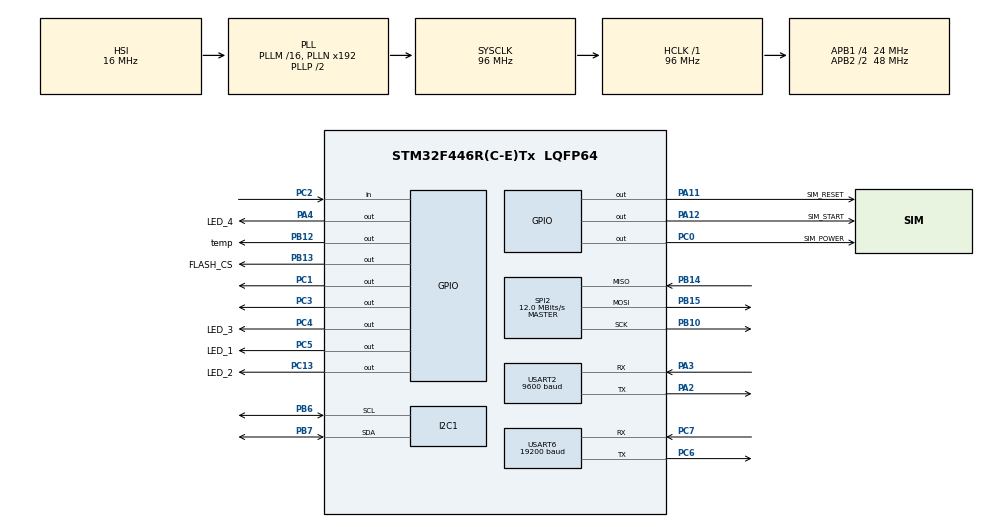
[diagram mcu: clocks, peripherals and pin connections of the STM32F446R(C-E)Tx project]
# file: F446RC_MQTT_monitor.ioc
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Dma.Request0=USART2_RX
Dma.Request1=USART2_TX
Dma.Request2=USART6_RX
Dma.Request3=USART6_TX
Dma.USART2_RX.0.Direction=DMA_PERIPH_TO_MEMORY
Dma.USART2_RX.0.FIFOMode=DMA_FIFOMODE_DISABLE
Dma.USART2_RX.0.Instance=DMA1_Stream5
Dma.USART2_RX.0.MemDataAlignment=DMA_MDATAALIGN_BYTE
Dma.USART2_RX.0.MemInc=DMA_MINC_ENABLE
Dma.USART2_RX.0.Mode=DMA_NORMAL
Dma.USART2_RX.0.PeriphDataAlignment=DMA_PDATAALIGN_BYTE
Dma.USART2_RX.0.PeriphInc=DMA_PINC_DISABLE
Dma.USART2_RX.0.Priority=DMA_PRIORITY_LOW
Dma.USART2_TX.1.Direction=DMA_MEMORY_TO_PERIPH
Dma.USART2_TX.1.FIFOMode=DMA_FIFOMODE_DISABLE
Dma.USART2_TX.1.Instance=DMA1_Stream6
Dma.USART2_TX.1.MemDataAlignment=DMA_MDATAALIGN_BYTE
Dma.USART2_TX.1.MemInc=DMA_MINC_ENABLE
Dma.USART2_TX.1.Mode=DMA_NORMAL
Dma.USART2_TX.1.PeriphDataAlignment=DMA_PDATAALIGN_BYTE
Dma.USART2_TX.1.PeriphInc=DMA_PINC_DISABLE
Dma.USART2_TX.1.Priority=DMA_PRIORITY_LOW
Dma.USART6_RX.2.Direction=DMA_PERIPH_TO_MEMORY
Dma.USART6_RX.2.FIFOMode=DMA_FIFOMODE_DISABLE
Dma.USART6_RX.2.Instance=DMA2_Stream1
Dma.USART6_RX.2.MemDataAlignment=DMA_MDATAALIGN_BYTE
Dma.USART6_RX.2.MemInc=DMA_MINC_ENABLE
Dma.USART6_RX.2.Mode=DMA_NORMAL
Dma.USART6_RX.2.PeriphDataAlignment=DMA_PDATAALIGN_BYTE
Dma.USART6_RX.2.PeriphInc=DMA_PINC_DISABLE
Dma.USART6_RX.2.Priority=DMA_PRIORITY_LOW
Dma.USART6_TX.3.Direction=DMA_MEMORY_TO_PERIPH
Dma.USART6_TX.3.FIFOMode=DMA_FIFOMODE_DISABLE
Dma.USART6_TX.3.Instance=DMA2_Stream6
Dma.USART6_TX.3.MemDataAlignment=DMA_MDATAALIGN_BYTE
Dma.USART6_TX.3.MemInc=DMA_MINC_ENABLE
Dma.USART6_TX.3.Mode=DMA_NORMAL
Dma.USART6_TX.3.PeriphDataAlignment=DMA_PDATAALIGN_BYTE
Dma.USART6_TX.3.PeriphInc=DMA_PINC_DISABLE
Dma.USART6_TX.3.Priority=DMA_PRIORITY_LOW
FREERTOS.BinarySemaphores01=PINGSem,Dynamic,NULL;SemGetData,Dynamic,NULL
FREERTOS.Mutexes01=UART1Mutex,Dynamic,NULL
FREERTOS.Queues01=debugQueue,10,message_type,0,Dynamic,NULL,NULL;SIM800SendQueue,10,message_type,0,Dynamic,NULL,NULL;RxSIM800Queue,10,message_type,0,Dynamic,NULL,NULL
FREERTOS.Tasks01=defaultTask,24,128,StartDefaultTask,Default,NULL,Dynamic,NULL,NULL;GetDataTask,25,128,StartGetDataTask,Default,NULL,Dynamic,NULL,NULL;DebugTask,24,128,StartDebugTask,Default,NULL,Dynamic,NULL,NULL;SIM800SendTask,24,256,StartSIM800SendTask,Default,NULL,Dynamic,NULL,NULL;PINGTask,24,256,PINGStartTask,Default,NULL,Dynamic,NULL,NULL;SIM800StartTask,26,256,StartSIM800Task,Default,NULL,Dynamic,NULL,NULL;MQTTConnectTask,24,256,StartMQTTConnectTask,Default,NULL,Dynamic,NULL,NULL;MessHandlerTask,24,256,StartMessHandlerTask,Default,NULL,Dynamic,NULL,NULL;myTaskGetFirm,25,512,StartGetFirmware,Default,NULL,Dynamic,NULL,NULL
FREERTOS.Timers01=PingTimer,CallbackPingTimer,osTimerPeriodic,Default,NULL,Dynamic,NULL;DataTimer,CallbackDataTimer,osTimerPeriodic,Default,NULL,Dynamic,NULL
Mcu.Family=STM32F4
Mcu.Name=STM32F446R(C-E)Tx
Mcu.Package=LQFP64
NVIC.DMA1_Stream5_IRQn=true\:5\:0\:false\:false\:true\:true\:false\:true\:true
NVIC.DMA1_Stream6_IRQn=true\:5\:0\:false\:false\:true\:true\:false\:true\:true
NVIC.DMA2_Stream1_IRQn=true\:5\:0\:false\:false\:true\:true\:false\:true\:true
NVIC.DMA2_Stream6_IRQn=true\:5\:0\:false\:false\:true\:true\:false\:true\:true
NVIC.PriorityGroup=NVIC_PRIORITYGROUP_4
NVIC.TIM1_UP_TIM10_IRQn=true\:0\:0\:false\:false\:true\:false\:false\:true\:true
NVIC.TimeBase=TIM1_UP_TIM10_IRQn
NVIC.TimeBaseIP=TIM1
NVIC.USART2_IRQn=true\:5\:0\:false\:false\:true\:true\:true\:true\:true
NVIC.USART6_IRQn=true\:5\:0\:false\:false\:true\:true\:true\:true\:true
PA11.GPIO_Label=SIM_RESET
PA11.Signal=GPIO_Output
PA12.GPIO_Label=SIM_START
PA12.Signal=GPIO_Output
PA13.Mode=Serial_Wire
PA13.Signal=SYS_JTMS-SWDIO
PA14.Mode=Serial_Wire
PA14.Signal=SYS_JTCK-SWCLK
PA2.Mode=Asynchronous
PA2.Signal=USART2_TX
PA3.Mode=Asynchronous
PA3.Signal=USART2_RX
PA4.GPIO_Label=LED_4
PA4.PinState=GPIO_PIN_SET
PA4.Signal=GPIO_Output
PB10.Mode=Full_Duplex_Master
PB10.Signal=SPI2_SCK
PB12.GPIO_Label=temp
PB12.Signal=GPIO_Output
PB13.GPIO_Label=FLASH_CS
PB13.PinState=GPIO_PIN_SET
PB13.Signal=GPIO_Output
PB14.Mode=Full_Duplex_Master
PB14.Signal=SPI2_MISO
PB15.Mode=Full_Duplex_Master
PB15.Signal=SPI2_MOSI
PB6.Mode=I2C
PB6.Signal=I2C1_SCL
PB7.Mode=I2C
PB7.Signal=I2C1_SDA
PC0.GPIO_Label=SIM_POWER
PC0.Signal=GPIO_Output
PC1.PinState=GPIO_PIN_SET
PC1.Signal=GPIO_Output
PC13.GPIO_Label=LED_2
PC13.PinState=GPIO_PIN_SET
PC13.Signal=GPIO_Output
PC2.Signal=GPIO_Input
PC3.PinState=GPIO_PIN_SET
PC3.Signal=GPIO_Output
PC4.GPIO_Label=LED_3
PC4.PinState=GPIO_PIN_SET
PC4.Signal=GPIO_Output
PC5.GPIO_Label=LED_1
PC5.PinState=GPIO_PIN_SET
PC5.Signal=GPIO_Output
PC6.Mode=Asynchronous
PC6.Signal=USART6_TX
PC7.Mode=Asynchronous
PC7.Signal=USART6_RX
ProjectManager.HeapSize=0x200
ProjectManager.StackSize=0x400
ProjectManager.TargetToolchain=STM32CubeIDE
RCC.AHBFreq_Value=96000000
RCC.APB1CLKDivider=RCC_HCLK_DIV4
RCC.APB1Freq_Value=24000000
RCC.APB1TimFreq_Value=48000000
RCC.APB2CLKDivider=RCC_HCLK_DIV2
RCC.APB2Freq_Value=48000000
RCC.APB2TimFreq_Value=96000000
RCC.CortexFreq_Value=96000000
RCC.HCLKFreq_Value=96000000
RCC.SYSCLKFreq_VALUE=96000000
RCC.SYSCLKSource=RCC_SYSCLKSOURCE_PLLCLK
RCC.USBFreq_Value=96000000
RCC.VCOOutputFreq_Value=192000000
SPI2.CalculateBaudRate=12.0 MBits/s
SPI2.Direction=SPI_DIRECTION_2LINES
SPI2.Mode=SPI_MODE_MASTER
SPI2.VirtualType=VM_MASTER
USART2.BaudRate=9600
USART2.VirtualMode=VM_ASYNC
USART6.BaudRate=19200
USART6.VirtualMode=VM_ASYNC
VP_FREERTOS_VS_CMSIS_V2.Mode=CMSIS_V2
VP_SYS_VS_tim1.Mode=TIM1
board=custom

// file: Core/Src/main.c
/* USER CODE BEGIN Header */
//!!!! COMMENT MQTTConnectTaskHandle, PINGTaskHandle, myTaskGetFirmHandle
//AND RESET ALL SEMAPHORES !!!!!!!
/**
  ******************************************************************************
  * @file           : main.c
  * @brief          : Main program body
  ******************************************************************************
  * @attention
  *
  * <h2><center>&copy; Copyright (c) 2022 STMicroelectronics.
  * All rights reserved.</center></h2>
  *
  * This software component is licensed by ST under BSD 3-Clause license,
  * the "License"; You may not use this file except in compliance with the
  * License. You may obtain a copy of the License at:
  *                        opensource.org/licenses/BSD-3-Clause
  *
  ******************************************************************************
  */
/* USER CODE END Header */
#include "main.h"
#include "cmsis_os.h"

/* USER CODE BEGIN Includes */
#include <string.h>
#include <stdlib.h>
#include "micro_delay.h"
#include "w25qxx.h"
#include "private_data.h"
#include "ModBusCRC.h"
#include "INA226.h"
/* USER CODE END Includes */

/* USER CODE BEGIN PD */
#define PING_TIME 50000  //period of sending ping package
#define BUFF_SIM_SIZE 120 //size of RX SIM buffer
#define MESSAGE_TYPE_BUFF_SIZE 90
#define GET_DATA_PERIOD 60000
/* USER CODE END PD */

/* USER CODE BEGIN PM */
typedef struct {
	char str[MESSAGE_TYPE_BUFF_SIZE];
} message_type;
/* USER CODE END PM */

I2C_HandleTypeDef hi2c1;

SPI_HandleTypeDef hspi2;

UART_HandleTypeDef huart2;
UART_HandleTypeDef huart6;
DMA_HandleTypeDef hdma_usart2_rx;
DMA_HandleTypeDef hdma_usart2_tx;
DMA_HandleTypeDef hdma_usart6_rx;
DMA_HandleTypeDef hdma_usart6_tx;

/* Definitions for defaultTask */
osThreadId_t defaultTaskHandle;
const osThreadAttr_t defaultTask_attributes = {
  .name = "defaultTask",
  .stack_size = 128 * 4,
  .priority = (osPriority_t) osPriorityNormal,
};
/* Definitions for GetDataTask */
osThreadId_t GetDataTaskHandle;
const osThreadAttr_t GetDataTask_attributes = {
  .name = "GetDataTask",
  .stack_size = 128 * 4,
  .priority = (osPriority_t) osPriorityNormal1,
};
/* Definitions for DebugTask */
osThreadId_t DebugTaskHandle;
const osThreadAttr_t DebugTask_attributes = {
  .name = "DebugTask",
  .stack_size = 128 * 4,
  .priority = (osPriority_t) osPriorityNormal,
};
/* Definitions for SIM800SendTask */
osThreadId_t SIM800SendTaskHandle;
const osThreadAttr_t SIM800SendTask_attributes = {
  .name = "SIM800SendTask",
  .stack_size = 256 * 4,
  .priority = (osPriority_t) osPriorityNormal,
};
/* Definitions for PINGTask */
osThreadId_t PINGTaskHandle;
const osThreadAttr_t PINGTask_attributes = {
  .name = "PINGTask",
  .stack_size = 256 * 4,
  .priority = (osPriority_t) osPriorityNormal,
};
/* Definitions for SIM800StartTask */
osThreadId_t SIM800StartTaskHandle;
const osThreadAttr_t SIM800StartTask_attributes = {
  .name = "SIM800StartTask",
  .stack_size = 256 * 4,
  .priority = (osPriority_t) osPriorityNormal2,
};
/* Definitions for MQTTConnectTask */
osThreadId_t MQTTConnectTaskHandle;
const osThreadAttr_t MQTTConnectTask_attributes = {
  .name = "MQTTConnectTask",
  .stack_size = 256 * 4,
  .priority = (osPriority_t) osPriorityNormal,
};
/* Definitions for MessHandlerTask */
osThreadId_t MessHandlerTaskHandle;
const osThreadAttr_t MessHandlerTask_attributes = {
  .name = "MessHandlerTask",
  .stack_size = 256 * 4,
  .priority = (osPriority_t) osPriorityNormal,
};
/* Definitions for myTaskGetFirm */
osThreadId_t myTaskGetFirmHandle;
const osThreadAttr_t myTaskGetFirm_attributes = {
  .name = "myTaskGetFirm",
  .stack_size = 512 * 4,
  .priority = (osPriority_t) osPriorityNormal1,
};
/* Definitions for debugQueue */
osMessageQueueId_t debugQueueHandle;
const osMessageQueueAttr_t debugQueue_attributes = {
  .name = "debugQueue"
};
/* Definitions for SIM800SendQueue */
osMessageQueueId_t SIM800SendQueueHandle;
const osMessageQueueAttr_t SIM800SendQueue_attributes = {
  .name = "SIM800SendQueue"
};
/* Definitions for RxSIM800Queue */
osMessageQueueId_t RxSIM800QueueHandle;
const osMessageQueueAttr_t RxSIM800Queue_attributes = {
  .name = "RxSIM800Queue"
};
/* Definitions for PingTimer */
osTimerId_t PingTimerHandle;
const osTimerAttr_t PingTimer_attributes = {
  .name = "PingTimer"
};
/* Definitions for DataTimer */
osTimerId_t DataTimerHandle;
const osTimerAttr_t DataTimer_attributes = {
  .name = "DataTimer"
};
/* Definitions for UART1Mutex */
osMutexId_t UART1MutexHandle;
const osMutexAttr_t UART1Mutex_attributes = {
  .name = "UART1Mutex"
};
/* Definitions for PINGSem */
osSemaphoreId_t PINGSemHandle;
const osSemaphoreAttr_t PINGSem_attributes = {
  .name = "PINGSem"
};
/* Definitions for SemGetData */
osSemaphoreId_t SemGetDataHandle;
const osSemaphoreAttr_t SemGetData_attributes = {
  .name = "SemGetData"
};
/* USER CODE BEGIN PV */

//flags
uint8_t Error_init = 0; //show that we have error on working SIM800
uint8_t Error_ping = 0; //show that we have error on send ping package
uint8_t Error_broker_connect = 0; //show that we have error on connect to broker

uint8_t Start_SIM800 = 0; //show that SIM800 started well
uint8_t RX = 0;  //show that SIM800 transmitted some data
uint8_t Broker_connect = 0; //show that SIM800 connect to broker
uint8_t Tech_ans_wait = 0; //show that we waiting special answer from module
uint8_t Get_data = 0; //show that we have ask from server to get data

// flags for UART2
uint8_t UART2_TX_finish;
uint8_t UART2_RX_finish;
uint8_t RS485_buf[20];

uint8_t str_SIM800[BUFF_SIM_SIZE] = {};
uint8_t SIM800BuffRx[BUFF_SIM_SIZE] = {}; //buffer for RX data from SIM800
uint8_t firmware_buf[400] = {};
message_type Data_Queue;

uint32_t tmp4;
uint32_t tmp5;
uint32_t tmp6;
uint8_t Size_of_firmwware[5] = {};

/* STRINGS */
uint8_t PING[] = "\xC0\0\0";
uint8_t PING_ASK[] = "\xD0\0\0";
uint8_t MQTT_CONNECT_ASK[] = "\0x20\x02\0";
uint8_t TOPIC[] = DEF_TOPIC;
uint8_t TOPIC_ASK[] = "\x90\x03\0";

/* USER CODE END PV */

void SystemClock_Config(void);
static void MX_GPIO_Init(void);
static void MX_DMA_Init(void);
static void MX_USART2_UART_Init(void);
static void MX_SPI2_Init(void);
static void MX_I2C1_Init(void);
static void MX_USART6_UART_Init(void);
void StartDefaultTask(void *argument);
void StartGetDataTask(void *argument);
void StartDebugTask(void *argument);
void StartSIM800SendTask(void *argument);
void PINGStartTask(void *argument);
void StartSIM800Task(void *argument);
void StartMQTTConnectTask(void *argument);
void StartMessHandlerTask(void *argument);
void StartGetFirmware(void *argument);
void CallbackPingTimer(void *argument);
void CallbackDataTimer(void *argument);

int main(void)
{
  /* USER CODE BEGIN 1 */
	/*__disable_irq();
	SCB->VTOR = 0x0800C000;
	__enable_irq();*/
  /* USER CODE END 1 */

  /* MCU Configuration--------------------------------------------------------*/

  /* Reset of all peripherals, Initializes the Flash interface and the Systick. */
  HAL_Init();

  /* Configure the system clock */
  SystemClock_Config();

  /* Initialize all configured peripherals */
  MX_GPIO_Init();
  MX_DMA_Init();
  MX_USART2_UART_Init();
  MX_SPI2_Init();
  MX_I2C1_Init();
  MX_USART6_UART_Init();
  /* USER CODE BEGIN 2 */
  INA226_setConfig(&hi2c1, INA226_ADDRESS, INA226_MODE_CONT_SHUNT_AND_BUS | INA226_AVG_1024);
  INA226_setCalibrationReg(&hi2c1, INA226_ADDRESS, INA226_CALIB_VAL);
  /* USER CODE END 2 */

  /* Init scheduler */
  osKernelInitialize();
  /* Create the mutex(es) */
  /* creation of UART1Mutex */
  UART1MutexHandle = osMutexNew(&UART1Mutex_attributes);

  /* Create the semaphores(s) */
  /* creation of PINGSem */
  PINGSemHandle = osSemaphoreNew(1, 0, &PINGSem_attributes);

  /* creation of SemGetData */
  SemGetDataHandle = osSemaphoreNew(1, 0, &SemGetData_attributes);

  /* Create the timer(s) */
  /* creation of PingTimer */
  PingTimerHandle = osTimerNew(CallbackPingTimer, osTimerPeriodic, NULL, &PingTimer_attributes);

  /* creation of DataTimer */
  DataTimerHandle = osTimerNew(CallbackDataTimer, osTimerPeriodic, NULL, &DataTimer_attributes);

  /* Create the queue(s) */
  /* creation of debugQueue */
  debugQueueHandle = osMessageQueueNew (10, sizeof(message_type), &debugQueue_attributes);

  /* creation of SIM800SendQueue */
  SIM800SendQueueHandle = osMessageQueueNew (10, sizeof(message_type), &SIM800SendQueue_attributes);

  /* creation of RxSIM800Queue */
  RxSIM800QueueHandle = osMessageQueueNew (10, sizeof(message_type), &RxSIM800Queue_attributes);

  /* Create the thread(s) */
  /* creation of defaultTask */
  defaultTaskHandle = osThreadNew(StartDefaultTask, NULL, &defaultTask_attributes);

  /* creation of GetDataTask */
  GetDataTaskHandle = osThreadNew(StartGetDataTask, NULL, &GetDataTask_attributes);

  /* creation of DebugTask */
  DebugTaskHandle = osThreadNew(StartDebugTask, NULL, &DebugTask_attributes);

  /* creation of SIM800SendTask */
  SIM800SendTaskHandle = osThreadNew(StartSIM800SendTask, NULL, &SIM800SendTask_attributes);

  /* creation of PINGTask */
  //PINGTaskHandle = osThreadNew(PINGStartTask, NULL, &PINGTask_attributes);

  /* creation of SIM800StartTask */
  SIM800StartTaskHandle = osThreadNew(StartSIM800Task, NULL, &SIM800StartTask_attributes);

  /* creation of MQTTConnectTask */
  //MQTTConnectTaskHandle = osThreadNew(StartMQTTConnectTask, NULL, &MQTTConnectTask_attributes);

  /* creation of MessHandlerTask */
  MessHandlerTaskHandle = osThreadNew(StartMessHandlerTask, NULL, &MessHandlerTask_attributes);

  /* creation of myTaskGetFirm */
  //myTaskGetFirmHandle = osThreadNew(StartGetFirmware, NULL, &myTaskGetFirm_attributes);

  /* Start scheduler */
  osKernelStart();

  /* We should never get here as control is now taken by the scheduler */
  /* Infinite loop */
  while (1)
  {

  }
}

void SystemClock_Config(void)
{
  RCC_OscInitTypeDef RCC_OscInitStruct = {0};
  RCC_ClkInitTypeDef RCC_ClkInitStruct = {0};

  /** Configure the main internal regulator output voltage
  */
  __HAL_RCC_PWR_CLK_ENABLE();
  __HAL_PWR_VOLTAGESCALING_CONFIG(PWR_REGULATOR_VOLTAGE_SCALE3);
  /** Initializes the RCC Oscillators according to the specified parameters
  * in the RCC_OscInitTypeDef structure.
  */
  RCC_OscInitStruct.OscillatorType = RCC_OSCILLATORTYPE_HSI;
  RCC_OscInitStruct.HSIState = RCC_HSI_ON;
  RCC_OscInitStruct.HSICalibrationValue = RCC_HSICALIBRATION_DEFAULT;
  RCC_OscInitStruct.PLL.PLLState = RCC_PLL_ON;
  RCC_OscInitStruct.PLL.PLLSource = RCC_PLLSOURCE_HSI;
  RCC_OscInitStruct.PLL.PLLM = 16;
  RCC_OscInitStruct.PLL.PLLN = 192;
  RCC_OscInitStruct.PLL.PLLP = RCC_PLLP_DIV2;
  RCC_OscInitStruct.PLL.PLLQ = 2;
  RCC_OscInitStruct.PLL.PLLR = 2;
  if (HAL_RCC_OscConfig(&RCC_OscInitStruct) != HAL_OK)
  {
    Error_Handler();
  }
  /** Initializes the CPU, AHB and APB buses clocks
  */
  RCC_ClkInitStruct.ClockType = RCC_CLOCKTYPE_HCLK|RCC_CLOCKTYPE_SYSCLK
                              |RCC_CLOCKTYPE_PCLK1|RCC_CLOCKTYPE_PCLK2;
  RCC_ClkInitStruct.SYSCLKSource = RCC_SYSCLKSOURCE_PLLCLK;
  RCC_ClkInitStruct.AHBCLKDivider = RCC_SYSCLK_DIV1;
  RCC_ClkInitStruct.APB1CLKDivider = RCC_HCLK_DIV4;
  RCC_ClkInitStruct.APB2CLKDivider = RCC_HCLK_DIV2;

  if (HAL_RCC_ClockConfig(&RCC_ClkInitStruct, FLASH_LATENCY_3) != HAL_OK)
  {
    Error_Handler();
  }
}

static void MX_I2C1_Init(void)
{

  hi2c1.Instance = I2C1;
  hi2c1.Init.ClockSpeed = 100000;
  hi2c1.Init.DutyCycle = I2C_DUTYCYCLE_2;
  hi2c1.Init.OwnAddress1 = 0;
  hi2c1.Init.AddressingMode = I2C_ADDRESSINGMODE_7BIT;
  hi2c1.Init.DualAddressMode = I2C_DUALADDRESS_DISABLE;
  hi2c1.Init.OwnAddress2 = 0;
  hi2c1.Init.GeneralCallMode = I2C_GENERALCALL_DISABLE;
  hi2c1.Init.NoStretchMode = I2C_NOSTRETCH_DISABLE;
  if (HAL_I2C_Init(&hi2c1) != HAL_OK)
  {
    Error_Handler();
  }

}

static void MX_SPI2_Init(void)
{

  /* SPI2 parameter configuration*/
  hspi2.Instance = SPI2;
  hspi2.Init.Mode = SPI_MODE_MASTER;
  hspi2.Init.Direction = SPI_DIRECTION_2LINES;
  hspi2.Init.DataSize = SPI_DATASIZE_8BIT;
  hspi2.Init.CLKPolarity = SPI_POLARITY_LOW;
  hspi2.Init.CLKPhase = SPI_PHASE_1EDGE;
  hspi2.Init.NSS = SPI_NSS_SOFT;
  hspi2.Init.BaudRatePrescaler = SPI_BAUDRATEPRESCALER_2;
  hspi2.Init.FirstBit = SPI_FIRSTBIT_MSB;
  hspi2.Init.TIMode = SPI_TIMODE_DISABLE;
  hspi2.Init.CRCCalculation = SPI_CRCCALCULATION_DISABLE;
  hspi2.Init.CRCPolynomial = 10;
  if (HAL_SPI_Init(&hspi2) != HAL_OK)
  {
    Error_Handler();
  }

}

static void MX_USART2_UART_Init(void)
{

  huart2.Instance = USART2;
  huart2.Init.BaudRate = 9600;
  huart2.Init.WordLength = UART_WORDLENGTH_8B;
  huart2.Init.StopBits = UART_STOPBITS_1;
  huart2.Init.Parity = UART_PARITY_NONE;
  huart2.Init.Mode = UART_MODE_TX_RX;
  huart2.Init.HwFlowCtl = UART_HWCONTROL_NONE;
  huart2.Init.OverSampling = UART_OVERSAMPLING_16;
  if (HAL_UART_Init(&huart2) != HAL_OK)
  {
    Error_Handler();
  }

}

static void MX_USART6_UART_Init(void)
{

  huart6.Instance = USART6;
  huart6.Init.BaudRate = 19200;
  huart6.Init.WordLength = UART_WORDLENGTH_8B;
  huart6.Init.StopBits = UART_STOPBITS_1;
  huart6.Init.Parity = UART_PARITY_NONE;
  huart6.Init.Mode = UART_MODE_TX_RX;
  huart6.Init.HwFlowCtl = UART_HWCONTROL_NONE;
  huart6.Init.OverSampling = UART_OVERSAMPLING_16;
  if (HAL_UART_Init(&huart6) != HAL_OK)
  {
    Error_Handler();
  }

}

static void MX_DMA_Init(void)
{

  /* DMA controller clock enable */
  __HAL_RCC_DMA1_CLK_ENABLE();
  __HAL_RCC_DMA2_CLK_ENABLE();

  /* DMA interrupt init */
  /* DMA1_Stream5_IRQn interrupt configuration */
  HAL_NVIC_SetPriority(DMA1_Stream5_IRQn, 5, 0);
  HAL_NVIC_EnableIRQ(DMA1_Stream5_IRQn);
  /* DMA1_Stream6_IRQn interrupt configuration */
  HAL_NVIC_SetPriority(DMA1_Stream6_IRQn, 5, 0);
  HAL_NVIC_EnableIRQ(DMA1_Stream6_IRQn);
  /* DMA2_Stream1_IRQn interrupt configuration */
  HAL_NVIC_SetPriority(DMA2_Stream1_IRQn, 5, 0);
  HAL_NVIC_EnableIRQ(DMA2_Stream1_IRQn);
  /* DMA2_Stream6_IRQn interrupt configuration */
  HAL_NVIC_SetPriority(DMA2_Stream6_IRQn, 5, 0);
  HAL_NVIC_EnableIRQ(DMA2_Stream6_IRQn);

}

static void MX_GPIO_Init(void)
{
  GPIO_InitTypeDef GPIO_InitStruct = {0};

  /* GPIO Ports Clock Enable */
  __HAL_RCC_GPIOC_CLK_ENABLE();
  __HAL_RCC_GPIOA_CLK_ENABLE();
  __HAL_RCC_GPIOB_CLK_ENABLE();

  /*Configure GPIO pin Output Level */
  HAL_GPIO_WritePin(GPIOC, LED_2_Pin|GPIO_PIN_1|GPIO_PIN_3|LED_3_Pin
                          |LED_1_Pin, GPIO_PIN_SET);

  /*Configure GPIO pin Output Level */
  HAL_GPIO_WritePin(SIM_POWER_GPIO_Port, SIM_POWER_Pin, GPIO_PIN_RESET);

  /*Configure GPIO pin Output Level */
  HAL_GPIO_WritePin(LED_4_GPIO_Port, LED_4_Pin, GPIO_PIN_SET);

  /*Configure GPIO pin Output Level */
  HAL_GPIO_WritePin(temp_GPIO_Port, temp_Pin, GPIO_PIN_RESET);

  /*Configure GPIO pin Output Level */
  HAL_GPIO_WritePin(FLASH_CS_GPIO_Port, FLASH_CS_Pin, GPIO_PIN_SET);

  /*Configure GPIO pin Output Level */
  HAL_GPIO_WritePin(GPIOA, SIM_RESET_Pin|SIM_START_Pin, GPIO_PIN_RESET);

  /*Configure GPIO pins : LED_2_Pin SIM_POWER_Pin PC1 PC3
                           LED_3_Pin LED_1_Pin */
  GPIO_InitStruct.Pin = LED_2_Pin|SIM_POWER_Pin|GPIO_PIN_1|GPIO_PIN_3
                          |LED_3_Pin|LED_1_Pin;
  GPIO_InitStruct.Mode = GPIO_MODE_OUTPUT_PP;
  GPIO_InitStruct.Pull = GPIO_NOPULL;
  GPIO_InitStruct.Speed = GPIO_SPEED_FREQ_LOW;
  HAL_GPIO_Init(GPIOC, &GPIO_InitStruct);

  /*Configure GPIO pin : PC2 */
  GPIO_InitStruct.Pin = GPIO_PIN_2;
  GPIO_InitStruct.Mode = GPIO_MODE_INPUT;
  GPIO_InitStruct.Pull = GPIO_NOPULL;
  HAL_GPIO_Init(GPIOC, &GPIO_InitStruct);

  /*Configure GPIO pins : LED_4_Pin SIM_RESET_Pin SIM_START_Pin */
  GPIO_InitStruct.Pin = LED_4_Pin|SIM_RESET_Pin|SIM_START_Pin;
  GPIO_InitStruct.Mode = GPIO_MODE_OUTPUT_PP;
  GPIO_InitStruct.Pull = GPIO_NOPULL;
  GPIO_InitStruct.Speed = GPIO_SPEED_FREQ_LOW;
  HAL_GPIO_Init(GPIOA, &GPIO_InitStruct);

  /*Configure GPIO pins : temp_Pin FLASH_CS_Pin */
  GPIO_InitStruct.Pin = temp_Pin|FLASH_CS_Pin;
  GPIO_InitStruct.Mode = GPIO_MODE_OUTPUT_PP;
  GPIO_InitStruct.Pull = GPIO_NOPULL;
  GPIO_InitStruct.Speed = GPIO_SPEED_FREQ_LOW;
  HAL_GPIO_Init(GPIOB, &GPIO_InitStruct);

}

/* USER CODE BEGIN 4 */

void HAL_UART_RxCpltCallback(UART_HandleTypeDef *huart)
{
	if(huart == &huart2)
	{
		UART2_RX_finish = 1;
	}
}

void HAL_UART_TxCpltCallback(UART_HandleTypeDef *huart)
{
	if(huart == &huart2)
	{
		UART2_TX_finish = 1;
	}
}

void SPI2_Init_Master(void)
{
	GPIO_InitTypeDef GPIO_InitStruct = {0};
	HAL_GPIO_WritePin(FLASH_CS_GPIO_Port, FLASH_CS_Pin, GPIO_PIN_SET);

	/*Configure GPIO pin : FLASH_CS_Pin */
	GPIO_InitStruct.Pin = FLASH_CS_Pin;
	GPIO_InitStruct.Mode = GPIO_MODE_OUTPUT_PP;
	GPIO_InitStruct.Pull = GPIO_NOPULL;
	GPIO_InitStruct.Speed = GPIO_SPEED_FREQ_LOW;
	HAL_GPIO_Init(FLASH_CS_GPIO_Port, &GPIO_InitStruct);

	hspi2.Init.Mode = SPI_MODE_MASTER;
	if (HAL_SPI_Init(&hspi2) != HAL_OK)
	{
		Error_Handler();
	}
}

/**
  * @brief  make string in MQTT protocol with message msg and topic TOPIC.
  * @param  send_MQTT_message[] String, where will be result.
  * @param  msg[] struct with message for sending with MQTT.
 */

void Make_MQTT_send_string(uint8_t send_MQTT_message[], message_type msg)
{
	send_MQTT_message[0] = 0x30;
    send_MQTT_message[1] = strlen(msg.str) + strlen(TOPIC) + 2;
    send_MQTT_message[2] = 0;
    send_MQTT_message[3] = strlen(TOPIC);
    sprintf(send_MQTT_message + 4,"%s",TOPIC);
    sprintf(send_MQTT_message + 4 + strlen(TOPIC),"%s",msg.str);
}

/**
  * @brief  Find string in Receive buffer SIM800.
  * @param  exm[] String, that we search in Receive buffer SIM800.
  * @retval Is string in Receive buffer SIM800.
 */

uint8_t String_in_SIM800BuffRx(uint8_t exm[])
{
	uint8_t len = strlen(exm);
	uint8_t ans = 0;
	for (uint8_t i = 0; i < BUFF_SIM_SIZE - len; i++)
	{
		if (SIM800BuffRx[i] == exm[0])
		{
			ans = 1;
			for (uint8_t k = 0; k < len; k++)
			{
				if (SIM800BuffRx[i+k] != exm[k])
				{
					ans = 0;
				}
			}
			if (ans)
				break;
		}
	}
	return ans;
}

uint8_t String_in_String(uint8_t str[], uint8_t size, uint8_t exm[])
{
	uint8_t len = strlen(exm);
	uint8_t ans = 0;
	for (uint8_t i = 0; i < size - len; i++)
	{
		if (str[i] == exm[0])
		{
			ans = 1;
			for (uint8_t k = 0; k < len; k++)
			{
				if (str[i+k] != exm[k])
				{
					ans = 0;
				}
			}
			if (ans)
				break;
		}
	}
	return ans;
}

void USER_UART_IRQHandler(UART_HandleTypeDef *huart)
{
	// off half_interupt
	// file stm32f1xx_hal_uart.c
	// comment
	// Set the UART DMA Half transfer complete callback
	// huart->hdmatx->XferHalfCpltCallback = UART_DMATxHalfCplt

	if(huart == &huart6) //Determine whether it is serial port 1
	{
		if(RESET != __HAL_UART_GET_FLAG(&huart6, UART_FLAG_IDLE))   //Judging whether it is idle interruption
		{
			HAL_UART_DMAStop(&huart6);
			__HAL_UART_CLEAR_IDLEFLAG(&huart6); //Clear idle interrupt sign (otherwise it will continue to enter interrupt)
			RX = 1;
			if (Broker_connect)
			{

				if (String_in_SIM800BuffRx(";;"))
				{
					memcpy(&(Data_Queue.str), SIM800BuffRx, MESSAGE_TYPE_BUFF_SIZE);
					memset(SIM800BuffRx, 0, BUFF_SIM_SIZE);
					osMessageQueuePut(RxSIM800QueueHandle, &Data_Queue, 0, NULL);
					HAL_UART_Receive_DMA(&huart6, SIM800BuffRx, BUFF_SIM_SIZE);
				}

				if (!Tech_ans_wait)
				{
					memset(SIM800BuffRx, 0, BUFF_SIM_SIZE);
					HAL_UART_Receive_DMA(&huart6, SIM800BuffRx, BUFF_SIM_SIZE);
				}

			}
			//HAL_UART_DMAStop(&huart1);
		}
	}
}

/**
  * @brief  Waiting special answer from SIM800.
  * @param  exm[] String, that we expect.
  * @retval Is special answer in Receive buffer SIM800.
  */
uint8_t SIM800_Ans(uint8_t exm[])
{
	RX = 0;
	Tech_ans_wait = 1;
	HAL_UART_Receive_DMA(&huart6, SIM800BuffRx, BUFF_SIM_SIZE);

	SCB_DEMCR |= CoreDebug_DEMCR_TRCENA_Msk; // permission counter
	DWT_CONTROL |= DWT_CTRL_CYCCNTENA_Msk;   // start counter

	uint32_t tacts = HAL_RCC_GetSysClockFreq() / 1000000;
	tacts *= 6000000; //timeout - 6s
	DWT->CYCCNT = 0; // clear counter
	while (RX != 1 && DWT->CYCCNT < tacts) {};
	Tech_ans_wait = 0;
	if (!String_in_SIM800BuffRx(exm))
	{
		return 0;
	}
	else
	{
		return 1;
	}
}
/* USER CODE END 4 */

void StartDefaultTask(void *argument)
{
  /* USER CODE BEGIN 5 */
  /* Infinite loop */
  for(;;)
  {
	  if (!Start_SIM800 && Error_init) //if we have problems with SIM800, restart it
	  {
		  Error_init = 0;
		  SIM800StartTaskHandle = osThreadNew(StartSIM800Task, NULL, &SIM800StartTask_attributes);
	  }

	  //show that program works
	  HAL_GPIO_TogglePin(LED_1_GPIO_Port, LED_1_Pin);
	  osDelay(500);

	  //if we have flag, start getting data
	  if (Get_data && Broker_connect)
	  {
		osSemaphoreRelease(SemGetDataHandle);
		Get_data = 0;
	  }
  }
  /* USER CODE END 5 */
}

void StartGetDataTask(void *argument)
{
  /* USER CODE BEGIN StartGetDataTask */
	message_type msg; //string for queue
	float V;
	float I;

	uint8_t power[6];
	uint16_t temp;
	uint16_t humidity;
	uint8_t people[6];
	uint8_t smoke[6];
	uint16_t RS485CRC;
  /* Infinite loop */
  for(;;)
  {
	  // wait semaphore for measuring temperature
	  if (osSemaphoreAcquire(SemGetDataHandle, osWaitForever) == osOK)
	  {

		  SCB_DEMCR |= CoreDebug_DEMCR_TRCENA_Msk; // permission counter
		  DWT_CONTROL |= DWT_CTRL_CYCCNTENA_Msk;   // start counter

		  // get temp and humidity
		  // make string
		  RS485_buf[0] = 0x01; //slave address
		  RS485_buf[1] = 0x04; //function code
		  RS485_buf[2] = 0x00; //
		  RS485_buf[3] = 0x01; // starting address
		  RS485_buf[4] = 0x00; //
		  RS485_buf[5] = 0x02; // count of register

		  // calculate CRC
		  RS485CRC = usMBCRC16(RS485_buf, 6);
		  RS485_buf[6] = RS485CRC;
		  RS485CRC >>= 8;
		  RS485_buf[7] = RS485CRC;

		  // send request
		  UART2_TX_finish = 0;
		  HAL_GPIO_WritePin(GPIOC, GPIO_PIN_3, 1);
		  HAL_UART_Transmit_DMA(&huart2, RS485_buf, 8);

		  uint32_t tacts = HAL_RCC_GetSysClockFreq() / 1000000;
		  tacts *= 3000000; //timeout - 3s
		  DWT->CYCCNT = 0; // clear counter
		  while (!UART2_TX_finish && DWT->CYCCNT < tacts) {}

		  // get ans
		  UART2_RX_finish = 0;
		  HAL_GPIO_WritePin(GPIOC, GPIO_PIN_3, 0);
		  HAL_UART_Receive_DMA(&huart2, RS485_buf, 9);
		  tacts = HAL_RCC_GetSysClockFreq() / 1000000;
		  tacts *= 3000000; //timeout - 3s
		  DWT->CYCCNT = 0; // clear counter
		  while (!UART2_RX_finish && DWT->CYCCNT < tacts) {}

		  // calculate CRC
		  RS485CRC = usMBCRC16(RS485_buf, 7);
		  uint16_t RS485CRC1 = (uint16_t)( RS485_buf[8] << 8 | RS485_buf[7] );
		  uint8_t ok = (RS485CRC1 == RS485CRC) ? 1 : 0;

		  if (ok)
		  {
			  temp = (uint16_t)( RS485_buf[3] << 8 | RS485_buf[4] );
			  humidity = (uint16_t)( RS485_buf[5] << 8 | RS485_buf[6] );

			  temp /= 10;
			  humidity /= 10;
		  }
		  else
		  {
			  temp = 146;
			  humidity = 146;
		  }

		  // get smoke and move
		  V = INA226_getBusV(&hi2c1, INA226_ADDRESS);
		  osDelay(100);
		  I = INA226_getCurrent(&hi2c1, INA226_ADDRESS);
		  osDelay(100);

		  if (V > (float)6.0)
			  strcpy(people, "true");
		  else
			  strcpy(people, "false");

		  if (I > (float)0.5)
			  strcpy(smoke, "true");
		  else
			  strcpy(smoke, "false");

		  //people = (V > (float)6.0) ? "true" : "false";
		  //smoke = (I > (float)0.5) ? "true" : "false";

		  // get power
		  //power = (!HAL_GPIO_ReadPin(GPIOC, GPIO_PIN_2)) ? "true" : "false";

		  if (!HAL_GPIO_ReadPin(GPIOC, GPIO_PIN_2))
		  	  strcpy(power, "true");
		  else
			  strcpy(power, "false");

		  // put string with data to queue
		  sprintf(&(msg.str), "{\"temp\":%d,\"humidity\":%d,\"power\":%s,\"people\":%s,\"smoke\":%s}\r\n\0",temp, humidity, power, people, smoke);
		  osMessageQueuePut(SIM800SendQueueHandle, &msg, 0, osWaitForever);

	  }
  }
  /* USER CODE END StartGetDataTask */
}

void StartDebugTask(void *argument)
{
  /* USER CODE BEGIN StartDebugTask */
	message_type msg;
  /* Infinite loop */
  for(;;)
  {
	  if (osMessageQueueGet(debugQueueHandle, &msg, 0, osWaitForever) == osOK)
	  {
		  //HAL_UART_Transmit_DMA(&huart2, msg.str, MESSAGE_TYPE_BUFF_SIZE);
	  }
  }
  /* USER CODE END StartDebugTask */
}

void StartSIM800SendTask(void *argument)
{
  /* USER CODE BEGIN StartSIM800SendTask */
	message_type msg;

	//+ message_len(1 byte) + topic_len(2 bytes) + topic + message
    uint8_t send_MQTT_message[BUFF_SIM_SIZE] = {};
    uint8_t ans;
  /* Infinite loop */
  for(;;)
  {
	  if (osMessageQueueGet(SIM800SendQueueHandle, &msg, 0, osWaitForever) == osOK)
	  {
		  if (osMutexAcquire(UART1MutexHandle, osWaitForever) == osOK)
		  {
			  __HAL_UART_ENABLE_IT(&huart6, UART_IT_IDLE);

			  memset(SIM800BuffRx, 0, BUFF_SIM_SIZE);
			  sprintf(send_MQTT_message,"AT+CIPSEND=%d\r\n\0",strlen(msg.str) + strlen(TOPIC) + 4);
			  HAL_UART_Transmit_DMA(&huart6, send_MQTT_message, strlen(send_MQTT_message));
			  ans = SIM800_Ans(">");
			  if (!ans)
			  {

			  }
			  memset(SIM800BuffRx, 0, BUFF_SIM_SIZE);
			  osDelay(100);

			  //make string for transmit
			  Make_MQTT_send_string(send_MQTT_message, msg);
			  HAL_UART_Transmit_DMA(&huart6, send_MQTT_message, strlen(msg.str) + strlen(TOPIC) + 4);

			  ans = SIM800_Ans("\x30"); //our transmited message
			  if (!ans)
			  {
				  memset(SIM800BuffRx, 0, BUFF_SIM_SIZE);
				  ans = SIM800_Ans("\x30"); //our transmited message
				  if (!ans)
				  {

				  }
			  }

			  memset(SIM800BuffRx, 0, BUFF_SIM_SIZE);
			  HAL_UART_Receive_DMA(&huart6, SIM800BuffRx, BUFF_SIM_SIZE);
			  osMutexRelease(UART1MutexHandle); //release UART for SIM800
		  }
	  }
  }
  /* USER CODE END StartSIM800SendTask */
}

void PINGStartTask(void *argument)
{
  /* USER CODE BEGIN PINGStartTask */
	message_type msg;
	uint8_t send_MQTT_message[BUFF_SIM_SIZE] = {};
	uint8_t ans = 0;
  /* Infinite loop */
  for(;;)
  {
	  if (osSemaphoreAcquire(PINGSemHandle, osWaitForever) == osOK)
	  {
		  if (osMutexAcquire(UART1MutexHandle, osWaitForever) == osOK)
		  {

			  memset(SIM800BuffRx, 0, BUFF_SIM_SIZE);
			  sprintf(send_MQTT_message,"AT+CIPSEND=2\r\n\0");
			  HAL_UART_Transmit_DMA(&huart6, send_MQTT_message, strlen(send_MQTT_message));
			  ans = SIM800_Ans(">");
			  if (!ans)
			  {
				  strcpy(&(msg.str), "FAILE_send_PING1\r\n\0");
				  osMessageQueuePut(debugQueueHandle, &msg, 0, osWaitForever);
				  Error_ping = 1;
				  //HAL_GPIO_WritePin(GPIOC, GPIO_PIN_3, 1); //signal for error
				  osMutexRelease(UART1MutexHandle); //release UART for SIM800
				  //start task to try reconnect
				  MQTTConnectTaskHandle = osThreadNew(StartMQTTConnectTask, NULL, &MQTTConnectTask_attributes);
				  //delete this thread
				  osThreadTerminate(PINGTaskHandle);
			  }
			  osDelay(200);
			  memset(SIM800BuffRx, 0, BUFF_SIM_SIZE);
			  HAL_UART_Transmit_DMA(&huart6, PING, 2);
			  ans = SIM800_Ans(PING);
			  if (!ans)
			  {
				  strcpy(&(msg.str), "FAILE_send_PING2\r\n\0");
				  osMessageQueuePut(debugQueueHandle, &msg, 0, osWaitForever);
				  Error_ping = 1;
				  //HAL_GPIO_WritePin(GPIOC, GPIO_PIN_3, 1);
				  osMutexRelease(UART1MutexHandle);
				  MQTTConnectTaskHandle = osThreadNew(StartMQTTConnectTask, NULL, &MQTTConnectTask_attributes);
				  osThreadTerminate(PINGTaskHandle);
			  }
			  memset(SIM800BuffRx, 0, BUFF_SIM_SIZE);
			  ans = SIM800_Ans(PING_ASK);
			  if (!ans)
			  {
				  memset(SIM800BuffRx, 0, BUFF_SIM_SIZE);
				  ans = SIM800_Ans(PING_ASK);
				  if (!ans)
				  {
					  strcpy(&(msg.str), "FAILE_send_PING3\r\n\0");
					  osMessageQueuePut(debugQueueHandle, &msg, 0, osWaitForever);
					  Error_ping = 1;
					  //HAL_GPIO_WritePin(GPIOC, GPIO_PIN_3, 1);
					  osMutexRelease(UART1MutexHandle);
					  MQTTConnectTaskHandle = osThreadNew(StartMQTTConnectTask, NULL, &MQTTConnectTask_attributes);
					  osThreadTerminate(PINGTaskHandle);
				  }
			  }

			  strcpy(&(msg.str), "PING_SEND_OK\r\n\0");
			  osMessageQueuePut(debugQueueHandle, &msg, 0, osWaitForever);

			  HAL_UART_Receive_DMA(&huart6, SIM800BuffRx, BUFF_SIM_SIZE);
			  osMutexRelease(UART1MutexHandle);
		  }
	  }
  }
  /* USER CODE END PINGStartTask */
}

void StartSIM800Task(void *argument)
{
  /* USER CODE BEGIN StartSIM800Task */

	message_type msg; // string for debug message
	uint8_t ans = 0; //is one string in another

  /* Infinite loop */
  for(;;)
  {
	  Error_init = 0;
	  __HAL_UART_ENABLE_IT(&huart6, UART_IT_IDLE);

start:

		//Hardware reset of module

		HAL_GPIO_WritePin(SIM_START_GPIO_Port, SIM_START_Pin, RESET);
		osDelay(500);
		HAL_GPIO_WritePin(SIM_START_GPIO_Port, SIM_START_Pin, SET);
		osDelay(8000);

	  	//send initializing data

	  	sprintf(str_SIM800,"ATZ\r\n\0");
	  	HAL_UART_Transmit_IT(&huart6, str_SIM800, strlen(str_SIM800));
	  	osDelay(6000);

	  	memset(SIM800BuffRx, 0, BUFF_SIM_SIZE); //clear receive buffer
	  	sprintf(str_SIM800,"AT+CIPMODE=0\r\n\0"); //make string for send
	  	HAL_UART_Transmit_IT(&huart6, str_SIM800, strlen(str_SIM800)); //send string
	  	ans = SIM800_Ans("OK"); //waiting answer, that we transmit in function
	  	if (!ans)
	  	{
	  		strcpy(&(msg.str), "FAILE_CIPMODE\r\n\0");
	  		osMessageQueuePut(debugQueueHandle, &msg, 0, osWaitForever);
	  		goto start;
	  	}
	  	osDelay(300);

	  	memset(SIM800BuffRx, 0, BUFF_SIM_SIZE);
	  	sprintf(str_SIM800,"AT+CIPMUX=0\r\n\0");
	  	HAL_UART_Transmit_IT(&huart6, str_SIM800, strlen(str_SIM800));
	  	ans = SIM800_Ans("OK");
	  	if (!ans)
		{
			strcpy(&(msg.str), "FAILE_CIPMUX\r\n\0");
			osMessageQueuePut(debugQueueHandle, &msg, 0, osWaitForever);
			goto start;
		}
		osDelay(300);

	  	memset(SIM800BuffRx, 0, BUFF_SIM_SIZE);
	  	sprintf(str_SIM800,"AT+CIPSTATUS\r\n\0");
	  	HAL_UART_Transmit_IT(&huart6, str_SIM800, strlen(str_SIM800));
	  	ans = SIM800_Ans("OK");
	  	if (!ans)
		{
			strcpy(&(msg.str), "FAILE_CIPSTATUS\r\n\0");
			osMessageQueuePut(debugQueueHandle, &msg, 0, osWaitForever);
			goto start;
		}
		osDelay(300);

	  	memset(SIM800BuffRx, 0, BUFF_SIM_SIZE);
	  	sprintf(str_SIM800,"AT+CIPRXGET=0\r\n\0");
	  	HAL_UART_Transmit_IT(&huart6, str_SIM800, strlen(str_SIM800));
	  	ans = SIM800_Ans("OK");
	  	if (!ans)
		{
			strcpy(&(msg.str), "FAILE_CIPRXGET\r\n\0");
			osMessageQueuePut(debugQueueHandle, &msg, 0, osWaitForever);
			goto start;
		}
		osDelay(300);

	  	memset(SIM800BuffRx, 0, BUFF_SIM_SIZE);
	  	sprintf(str_SIM800,"AT+CSTT=\"internet.beeline.ru\",\"beeline\",\"beeline\"\r\n\0");
	  	HAL_UART_Transmit_IT(&huart6, str_SIM800, strlen(str_SIM800));
	  	ans = SIM800_Ans("OK");
	  	if (!ans)
		{
			strcpy(&(msg.str), "FAILE_CSTT\r\n\0");
			osMessageQueuePut(debugQueueHandle, &msg, 0, osWaitForever);
			goto start;
		}
		osDelay(300);

	  	memset(SIM800BuffRx, 0, BUFF_SIM_SIZE);
	  	sprintf(str_SIM800,"AT+CIPSTATUS\r\n\0");
	  	HAL_UART_Transmit_IT(&huart6, str_SIM800, strlen(str_SIM800));
	  	ans = SIM800_Ans("OK");
	  	if (!ans)
		{
			strcpy(&(msg.str), "FAILE_CIPSTATUS\r\n\0");
			osMessageQueuePut(debugQueueHandle, &msg, 0, osWaitForever);
			goto start;
		}
		osDelay(300);

	  	memset(SIM800BuffRx, 0, BUFF_SIM_SIZE);
	  	sprintf(str_SIM800,"AT+CIICR\r\n\0");
	  	HAL_UART_Transmit_IT(&huart6, str_SIM800, strlen(str_SIM800));
	  	ans = SIM800_Ans("AT+CIICR");
	  	memset(SIM800BuffRx, 0, BUFF_SIM_SIZE);
	  	ans = SIM800_Ans("OK");
	  	if (!ans)
		{
			strcpy(&(msg.str), "FAILE_CIICR\r\n\0");
			osMessageQueuePut(debugQueueHandle, &msg, 0, osWaitForever);
			goto start;
		}
		osDelay(500);

	  	memset(SIM800BuffRx, 0, BUFF_SIM_SIZE);
	  	sprintf(str_SIM800,"AT+CIPSTATUS\r\n\0");
	  	HAL_UART_Transmit_IT(&huart6, str_SIM800, strlen(str_SIM800));
	  	ans = SIM800_Ans("OK");
	  	if (!ans)
		{
			strcpy(&(msg.str), "FAILE_CIPSTATUS\r\n\0");
			osMessageQueuePut(debugQueueHandle, &msg, 0, osWaitForever);
			goto start;
		}
		osDelay(300);

	  	memset(SIM800BuffRx, 0, BUFF_SIM_SIZE);
	  	sprintf(str_SIM800,"AT+CIFSR\r\n\0");
	  	HAL_UART_Transmit_IT(&huart6, str_SIM800, strlen(str_SIM800));
	  	RX = 0;
	  	HAL_UART_Receive_DMA(&huart6, SIM800BuffRx, BUFF_SIM_SIZE);
	  	while (RX < 1) {};
	  	osDelay(300);

	  	memset(SIM800BuffRx, 0, BUFF_SIM_SIZE);
	  	sprintf(str_SIM800,"AT+CIPSTATUS\r\n\0");
	  	HAL_UART_Transmit_IT(&huart6, str_SIM800, strlen(str_SIM800));
	  	ans = SIM800_Ans("OK");
	  	if (!ans)
		{
			strcpy(&(msg.str), "FAILE_CIPSTATUS\r\n\0");
			osMessageQueuePut(debugQueueHandle, &msg, 0, osWaitForever);
			goto start;
		}
		osDelay(300);

		strcpy(&(msg.str), "START_SIM800_OK\r\n\0");
		osMessageQueuePut(debugQueueHandle, &msg, 0, osWaitForever);

	  	Start_SIM800 = 1; //module starting good
	  	osMutexRelease(UART1MutexHandle); //release UART1
	  	HAL_GPIO_WritePin(LED_2_GPIO_Port, LED_2_Pin, 0);
	  	//start thread to connect to broker
	  	MQTTConnectTaskHandle = osThreadNew(StartMQTTConnectTask, NULL, &MQTTConnectTask_attributes);
	  	osThreadTerminate(SIM800StartTaskHandle); //execute this thread

  }
  /* USER CODE END StartSIM800Task */
}

void StartMQTTConnectTask(void *argument)
{
  /* USER CODE BEGIN StartMQTTConnectTask */

	message_type msg; // string for debug message
	uint8_t ans; //is one string in another
	uint8_t send_MQTT_message[BUFF_SIM_SIZE] = {}; //message to SIM800
	uint8_t counter = 0; //counter of bad trying to connect to broker

  /* Infinite loop */
  for(;;)
  {

	  // waiting mutex
	  if (osMutexAcquire(UART1MutexHandle, osWaitForever) == osOK)
	  {
	  start:
		  if (counter > 5)
		  {
			  Error_init = 1;
			  //HAL_GPIO_WritePin(GPIOC, GPIO_PIN_2, 1);
			  Start_SIM800 = 0;
			  osMutexRelease(UART1MutexHandle);
			  osThreadTerminate(MQTTConnectTaskHandle);
		  }

		  __HAL_UART_ENABLE_IT(&huart6, UART_IT_IDLE);
		  memset(SIM800BuffRx, 0, BUFF_SIM_SIZE);
		  //sprintf(str_SIM800,"AT+CIPSTART=\"TCP\",\"broker.hivemq.com\",1883\r\0");
		  sprintf(str_SIM800,"AT+CIPSTART=\"TCP\",\"broker.emqx.io\",1883\r\n\0");
		  HAL_UART_Transmit_DMA(&huart6, str_SIM800, strlen(str_SIM800));
		  ans = SIM800_Ans("OK");
		  if (!ans)
		  {
			  strcpy(&(msg.str), "FAILE_connect1\r\n\0");
			  osMessageQueuePut(debugQueueHandle, &msg, 0, osWaitForever);
			  counter++;
			  goto start;
		  }
		  osDelay(300);

		  memset(SIM800BuffRx, 0, BUFF_SIM_SIZE);
		  ans = SIM800_Ans("OK");
		  if (!ans)
		  {
			  strcpy(&(msg.str), "FAILE_connect2\r\n\0");
			  osMessageQueuePut(debugQueueHandle, &msg, 0, osWaitForever);
			  counter++;
			  goto start;
		  }
		  osDelay(300);

		  memset(SIM800BuffRx, 0, BUFF_SIM_SIZE);
		  sprintf(str_SIM800,"AT+CIPSEND=14\r\n\0");
		  //sprintf(str_SIM800,"AT+CIPSEND=24\r\0");
		  HAL_UART_Transmit_DMA(&huart6, str_SIM800, strlen(str_SIM800));
		  ans = SIM800_Ans(">");
		  if (!ans)
		  {
			  strcpy(&(msg.str), "FAILE_send\r\n\0");
			  osMessageQueuePut(debugQueueHandle, &msg, 0, osWaitForever);
			  counter++;
			  goto start;
		  }
		  osDelay(300);

		  memset(SIM800BuffRx, 0, BUFF_SIM_SIZE);
		  uint8_t send_MQTT_init[50] = "\x10\x0C\0\x04MQTT\x04\x02\0\x3C\0\0\0";
		  HAL_UART_Transmit_DMA(&huart6, send_MQTT_init, 14);
		  //uint8_t send_MQTT_init[50] = "\x10\x16\0\x04MQTT\x04\x02\0\x3C\0\x0A\x34\x62\x58\x34\x56\x66\x47\x42\x51\x75\0";
		  //HAL_UART_Transmit_DMA(&huart1, send_MQTT_init, 24);
		  //osDelay(2000);

		  memset(SIM800BuffRx, 0, BUFF_SIM_SIZE);
		  ans = SIM800_Ans("\x10\x0C\0\x04MQTT\x04\x02\0\x3C\0\0\0");
		  if (!ans)
		  {
			  strcpy(&(msg.str), "FAILE_init_mqtt1\r\n\0");
			  osMessageQueuePut(debugQueueHandle, &msg, 0, osWaitForever);
			  counter++;
			  goto start;
		  }

		  memset(SIM800BuffRx, 0, BUFF_SIM_SIZE);
		  ans = SIM800_Ans(MQTT_CONNECT_ASK);
		  if (!ans)
		  {
			  memset(SIM800BuffRx, 0, BUFF_SIM_SIZE);
			  ans = SIM800_Ans(MQTT_CONNECT_ASK);
			  if (!ans)
			  {
				  strcpy(&(msg.str), "FAILE_init_mqtt2\r\n\0");
				  osMessageQueuePut(debugQueueHandle, &msg, 0, osWaitForever);
				  counter++;
				  goto start;
			  }
		  }
		  osDelay(100);

		  memset(SIM800BuffRx, 0, BUFF_SIM_SIZE);
		  sprintf(send_MQTT_message,"AT+CIPSEND=%d\r\n\0", strlen(TOPIC) + 7);
		  HAL_UART_Transmit_DMA(&huart6, send_MQTT_message, strlen(send_MQTT_message));
		  ans = SIM800_Ans(">");
		  if (!ans)
		  {
			  strcpy(&(msg.str), "FAILE_send1\r\n\0");
			  osMessageQueuePut(debugQueueHandle, &msg, 0, osWaitForever);
			  counter++;
			  goto start;
		  }
		  osDelay(100);
		  memset(SIM800BuffRx, 0, BUFF_SIM_SIZE);

		  //create packet to subscribe on topic
		  send_MQTT_message[0] = 0x82;
		  send_MQTT_message[1] = strlen(TOPIC) + 5;
		  send_MQTT_message[2] = 0;
		  send_MQTT_message[3] = 1;
		  send_MQTT_message[4] = 0;
		  send_MQTT_message[5] = strlen(TOPIC);
		  sprintf(send_MQTT_message + 6,"%s\0",TOPIC);
		  HAL_UART_Transmit_DMA(&huart6, send_MQTT_message, strlen(TOPIC) + 7);
		  ans = SIM800_Ans(send_MQTT_message);
		  if (!ans)
		  {
			  strcpy(&(msg.str), "FAILE_send2\r\n\0");
			  osMessageQueuePut(debugQueueHandle, &msg, 0, osWaitForever);
			  counter++;
			  goto start;
		  }
		  memset(SIM800BuffRx, 0, BUFF_SIM_SIZE);
		  ans = SIM800_Ans(TOPIC_ASK);
		  if (!ans)
		  {
			  memset(SIM800BuffRx, 0, BUFF_SIM_SIZE);
			  ans = SIM800_Ans(TOPIC_ASK);
			  if (!ans)
			  {
				  strcpy(&(msg.str), "FAILE_send3\r\n\0");
				  osMessageQueuePut(debugQueueHandle, &msg, 0, osWaitForever);
				  counter++;
				  goto start;
			  }
		  }

		  strcpy(&(msg.str), "MQTT_connect_OK\r\n\0");
		  osMessageQueuePut(debugQueueHandle, &msg, 0, osWaitForever);

		  Broker_connect = 1;
		  osTimerStart(PingTimerHandle, PING_TIME); //start ping timer
		  osTimerStart(DataTimerHandle, GET_DATA_PERIOD); //start ping timer
		  HAL_UART_Receive_DMA(&huart6, SIM800BuffRx, BUFF_SIM_SIZE); //start receive messages
		  Tech_ans_wait = 0;

		  HAL_GPIO_WritePin(LED_3_GPIO_Port, LED_3_Pin, 0);
		  //start receiving data from broker
		  osMutexRelease(UART1MutexHandle);
		  PINGTaskHandle = osThreadNew(PINGStartTask, NULL, &PINGTask_attributes);
		  sprintf(&(msg.str), "On the line, Firmware V0.94\r\n\0");
		  osMessageQueuePut(SIM800SendQueueHandle, &msg, 0, osWaitForever);
		  //HAL_UART_Receive_DMA(&huart1, SIM800BuffRx, BUFF_SIM_SIZE); //start receive messages
		  osThreadTerminate(MQTTConnectTaskHandle);
	  }

  }
  /* USER CODE END StartMQTTConnectTask */
}

void StartMessHandlerTask(void *argument)
{
  /* USER CODE BEGIN StartMessHandlerTask */
	message_type msg;
	message_type msg2;
  /* Infinite loop */
  for(;;)
  {
	  if (osMessageQueueGet(RxSIM800QueueHandle, &msg, 0, osWaitForever) == osOK)
	  {

		sprintf(&(msg2.str), "RX\r\n\0");
		osMessageQueuePut(SIM800SendQueueHandle, &msg2, 0, osWaitForever);
		if (String_in_String(msg.str,MESSAGE_TYPE_BUFF_SIZE,";;on"))
		{
			HAL_GPIO_WritePin(LED_4_GPIO_Port, LED_4_Pin, 0);
		}
		else if (String_in_String(msg.str,MESSAGE_TYPE_BUFF_SIZE,";;off"))
		{
			HAL_GPIO_WritePin(LED_4_GPIO_Port, LED_4_Pin, 1);
		}
		else if (String_in_String(msg.str,MESSAGE_TYPE_BUFF_SIZE,";;data"))
		{
			Get_data = 1;
		}
		else if (String_in_String(msg.str,MESSAGE_TYPE_BUFF_SIZE,";;updt"))
		{
			if (osMutexAcquire(UART1MutexHandle, osWaitForever) == osOK)
		    {
				memset(SIM800BuffRx, 0, BUFF_SIM_SIZE);
				sprintf(str_SIM800,"AT+CIPCLOSE\r\n\0");
				HAL_UART_Transmit_DMA(&huart6, str_SIM800, strlen(str_SIM800));
				osDelay(1000);
				osThreadTerminate(PINGTaskHandle);
				osThreadTerminate(SIM800SendTaskHandle);
				osThreadTerminate(defaultTaskHandle);
				osMutexRelease(UART1MutexHandle); //release UART for SIM800
				myTaskGetFirmHandle = osThreadNew(StartGetFirmware, NULL, &myTaskGetFirm_attributes);

		    }
		}
		else if (String_in_String(msg.str,MESSAGE_TYPE_BUFF_SIZE,";;rst"))
		{
			HAL_Delay(1000);
			HAL_NVIC_SystemReset();
		}
	  }
  }
  /* USER CODE END StartMessHandlerTask */
}

void StartGetFirmware(void *argument)
{
  /* USER CODE BEGIN StartGetFirmware */
	message_type msg; // string for debug message
	uint8_t ans; //is one string in another
	uint8_t send_MQTT_message[BUFF_SIM_SIZE] = {}; //message to SIM800
	uint32_t sector_of_firmware = 30;
	uint32_t firmware_count_bytes;
	uint8_t tmp2[30];
	uint8_t tmp3[30];
  /* Infinite loop */
  for(;;)
  {
	  __HAL_UART_ENABLE_IT(&huart6, UART_IT_IDLE);
	  memset(SIM800BuffRx, 0, BUFF_SIM_SIZE);
	  sprintf(str_SIM800,"AT+FTPMODE=1\r\n\0");
	  HAL_UART_Transmit_DMA(&huart6, str_SIM800, strlen(str_SIM800));
	  ans = SIM800_Ans("OK");
	  if (!ans)
	  {
		  memset(SIM800BuffRx, 0, BUFF_SIM_SIZE);
		  ans = SIM800_Ans("OK");
		  if (!ans)
		  {
			  strcpy(&(msg.str), "FTPMODE\r\n\0");
			  osMessageQueuePut(debugQueueHandle, &msg, 0, osWaitForever);
		  }
	  }
	  osDelay(300);

	  /*memset(SIM800BuffRx, 0, BUFF_SIM_SIZE);
	  sprintf(str_SIM800,"AT+FTPSSL=2\r\n\0");
	  HAL_UART_Transmit_DMA(&huart1, str_SIM800, strlen(str_SIM800));
	  ans = SIM800_Ans("OK");
	  if (!ans)
	  {
		  memset(SIM800BuffRx, 0, BUFF_SIM_SIZE);
		  ans = SIM800_Ans("OK");
		  if (!ans)
		  {
			  strcpy(&(msg.str), "FTPFTPSSL\r\n\0");
			  osMessageQueuePut(debugQueueHandle, &msg, 0, osWaitForever);
		  }
	  }
	  osDelay(300);*/

	  memset(SIM800BuffRx, 0, BUFF_SIM_SIZE);
	  sprintf(str_SIM800,"AT+FTPTYPE=I\r\n\0");
	  HAL_UART_Transmit_DMA(&huart6, str_SIM800, strlen(str_SIM800));
	  ans = SIM800_Ans("OK");
	  if (!ans)
	  {
		  memset(SIM800BuffRx, 0, BUFF_SIM_SIZE);
		  ans = SIM800_Ans("OK");
		  if (!ans)
		  {
			  strcpy(&(msg.str), "FTPTYPE\r\n\0");
			  osMessageQueuePut(debugQueueHandle, &msg, 0, osWaitForever);
		  }
	  }
	  osDelay(300);

	  memset(SIM800BuffRx, 0, BUFF_SIM_SIZE);
	  sprintf(str_SIM800,"AT+SAPBR=3,1,CONTYPE,GPRS\r\n\0");
	  HAL_UART_Transmit_DMA(&huart6, str_SIM800, strlen(str_SIM800));
	  ans = SIM800_Ans("OK");
	  if (!ans)
	  {
		  memset(SIM800BuffRx, 0, BUFF_SIM_SIZE);
		  ans = SIM800_Ans("OK");
		  if (!ans)
		  {
			  strcpy(&(msg.str), "SAPBR\r\n\0");
			  osMessageQueuePut(debugQueueHandle, &msg, 0, osWaitForever);
		  }
	  }
	  osDelay(300);

	  memset(SIM800BuffRx, 0, BUFF_SIM_SIZE);
	  sprintf(str_SIM800,"AT+SAPBR=3,1,APN,internet.beeline.ru\r\n\0");
	  HAL_UART_Transmit_DMA(&huart6, str_SIM800, strlen(str_SIM800));
	  ans = SIM800_Ans("OK");
	  if (!ans)
	  {
		  memset(SIM800BuffRx, 0, BUFF_SIM_SIZE);
		  ans = SIM800_Ans("OK");
		  if (!ans)
		  {
			  strcpy(&(msg.str), "SAPBR\r\n\0");
			  osMessageQueuePut(debugQueueHandle, &msg, 0, osWaitForever);
		  }
	  }
	  osDelay(300);

	  memset(SIM800BuffRx, 0, BUFF_SIM_SIZE);
	  sprintf(str_SIM800,"AT+SAPBR=1,1\r\n\0");
	  HAL_UART_Transmit_DMA(&huart6, str_SIM800, strlen(str_SIM800));
	  ans = SIM800_Ans("OK");
	  if (!ans)
	  {
		  memset(SIM800BuffRx, 0, BUFF_SIM_SIZE);
		  ans = SIM800_Ans("OK");
		  if (!ans)
		  {
			  strcpy(&(msg.str), "SAPBR\r\n\0");
			  osMessageQueuePut(debugQueueHandle, &msg, 0, osWaitForever);
		  }
	  }
	  osDelay(300);

	  memset(SIM800BuffRx, 0, BUFF_SIM_SIZE);
	  sprintf(str_SIM800,"AT+FTPCID=1\r\n\0");
	  HAL_UART_Transmit_DMA(&huart6, str_SIM800, strlen(str_SIM800));
	  ans = SIM800_Ans("OK");
	  if (!ans)
	  {
		  memset(SIM800BuffRx, 0, BUFF_SIM_SIZE);
		  ans = SIM800_Ans("OK");
		  if (!ans)
		  {
			  strcpy(&(msg.str), "FTPCID\r\n\0");
			  osMessageQueuePut(debugQueueHandle, &msg, 0, osWaitForever);
		  }
	  }
	  osDelay(300);

	  memset(SIM800BuffRx, 0, BUFF_SIM_SIZE);
	  sprintf(str_SIM800,"AT+FTPSERV=%s\r\n\0", DEF_IP_FTP);
	  HAL_UART_Transmit_DMA(&huart6, str_SIM800, strlen(str_SIM800));
	  ans = SIM800_Ans("OK");
	  if (!ans)
	  {
		  memset(SIM800BuffRx, 0, BUFF_SIM_SIZE);
		  ans = SIM800_Ans("OK");
		  if (!ans)
		  {
			  strcpy(&(msg.str), "FTPSERV\r\n\0");
			  osMessageQueuePut(debugQueueHandle, &msg, 0, osWaitForever);
		  }
	  }
	  osDelay(300);

	  memset(SIM800BuffRx, 0, BUFF_SIM_SIZE);
	  sprintf(str_SIM800,"AT+FTPUN=%s\r\n\0", DEF_USER_FTP);
	  HAL_UART_Transmit_DMA(&huart6, str_SIM800, strlen(str_SIM800));
	  ans = SIM800_Ans("OK");
	  if (!ans)
	  {
		  memset(SIM800BuffRx, 0, BUFF_SIM_SIZE);
		  ans = SIM800_Ans("OK");
		  if (!ans)
		  {
			  strcpy(&(msg.str), "FTPUN\r\n\0");
			  osMessageQueuePut(debugQueueHandle, &msg, 0, osWaitForever);
		  }
	  }
	  osDelay(300);

	  memset(SIM800BuffRx, 0, BUFF_SIM_SIZE);
	  sprintf(str_SIM800,"AT+FTPPW=%s\r\n\0", DEF_PASSWORD_FTP);
	  HAL_UART_Transmit_DMA(&huart6, str_SIM800, strlen(str_SIM800));
	  ans = SIM800_Ans("OK");
	  if (!ans)
	  {
		  memset(SIM800BuffRx, 0, BUFF_SIM_SIZE);
		  ans = SIM800_Ans("OK");
		  if (!ans)
		  {
			  strcpy(&(msg.str), "FTPPW\r\n\0");
			  osMessageQueuePut(debugQueueHandle, &msg, 0, osWaitForever);
		  }
	  }
	  osDelay(300);

	  memset(SIM800BuffRx, 0, BUFF_SIM_SIZE);
	  sprintf(str_SIM800,"AT+FTPGETPATH=/firmware/\r\n\0");
	  HAL_UART_Transmit_DMA(&huart6, str_SIM800, strlen(str_SIM800));
	  ans = SIM800_Ans("OK");
	  if (!ans)
	  {
		  memset(SIM800BuffRx, 0, BUFF_SIM_SIZE);
		  ans = SIM800_Ans("OK");
		  if (!ans)
		  {
			  strcpy(&(msg.str), "FTPGETPATH\r\n\0");
			  osMessageQueuePut(debugQueueHandle, &msg, 0, osWaitForever);
		  }
	  }
	  osDelay(300);

	  memset(SIM800BuffRx, 0, BUFF_SIM_SIZE);
	  sprintf(str_SIM800,"AT+FTPGETNAME=Firmware.txt\r\n\0");
	  HAL_UART_Transmit_DMA(&huart6, str_SIM800, strlen(str_SIM800));
	  ans = SIM800_Ans("OK");
	  if (!ans)
	  {
		  memset(SIM800BuffRx, 0, BUFF_SIM_SIZE);
		  ans = SIM800_Ans("OK");
		  if (!ans)
		  {
			  strcpy(&(msg.str), "FTPGETNAME\r\n\0");
			  osMessageQueuePut(debugQueueHandle, &msg, 0, osWaitForever);
		  }
	  }
	  osDelay(300);

	  memset(SIM800BuffRx, 0, BUFF_SIM_SIZE);
	  sprintf(str_SIM800,"AT+FTPGETTOFS=0,Firmware.txt\r\n\0");
	  HAL_UART_Transmit_DMA(&huart6, str_SIM800, strlen(str_SIM800));
	  ans = SIM800_Ans("OK");
	  if (!ans)
	  {
		  memset(SIM800BuffRx, 0, BUFF_SIM_SIZE);
		  ans = SIM800_Ans("OK");
		  if (!ans)
		  {
			  strcpy(&(msg.str), "FTPGETTOFS\r\n\0");
			  osMessageQueuePut(debugQueueHandle, &msg, 0, osWaitForever);
		  }
	  }
	  osDelay(300);

	  memset(SIM800BuffRx, 0, BUFF_SIM_SIZE);
	  RX = 0;
	  Tech_ans_wait = 1;
	  HAL_UART_Receive_DMA(&huart6, SIM800BuffRx, BUFF_SIM_SIZE);
	  while (RX != 1) {};
	  Tech_ans_wait = 0;

	  //good download
	  if (String_in_SIM800BuffRx("+FTPGETTOFS: "))
	  {
		  sscanf(SIM800BuffRx, "%s%2s%d", tmp2, tmp3, &firmware_count_bytes);

		  SPI2_Init_Master();
		  HAL_Delay(200);

		  W25qxx_Init();

		  uint32_t count_of_pages = (firmware_count_bytes / 256) + ((firmware_count_bytes % 256) ? 1 : 0);
		  uint32_t count_of_sectors = (firmware_count_bytes / 4096) + ((firmware_count_bytes % 4096) ? 1 : 0);
		  count_of_sectors++;

		  //start write from 30 sector
		  for (uint32_t i = 0; i <= count_of_sectors; i++)
		  {
			  // sectors for clear
			  uint32_t tmp = i + sector_of_firmware - 1;
			  W25qxx_EraseSector(tmp);
		  }

		  //writes size of firmware
		  tmp4 = (firmware_count_bytes & 0xFF0000) >> 16;
		  tmp5 = (firmware_count_bytes & 0xFF00) >> 8;
		  tmp6 = (firmware_count_bytes & 0xFF);
		  Size_of_firmwware[0] = tmp4;
		  Size_of_firmwware[1] = tmp5;
		  Size_of_firmwware[2] = tmp6;

		  int32_t page_start1 = 16 * (sector_of_firmware - 1);

		  W25qxx_WritePage(Size_of_firmwware, page_start1, 0, 3);

		  for (uint32_t i = 0; i < count_of_pages; i++)
		  {
			  int32_t start = i * 256;
			  //start += (i > 0) ? 1 : 0;

			  memset(firmware_buf, 0, 399);
			  sprintf(str_SIM800,"AT+FSREAD=C:\\User\\FTP\\Firmware.txt,1,256,%d\r\n\0", start);
			  HAL_UART_Transmit_DMA(&huart6, str_SIM800, strlen(str_SIM800));
			  RX = 0;
			  Tech_ans_wait = 1;
			  HAL_UART_Receive_DMA(&huart6, firmware_buf, 390);
			  HAL_GPIO_TogglePin(GPIOA, GPIO_PIN_6);
			  while (RX != 1) {};
			  HAL_GPIO_TogglePin(GPIOA, GPIO_PIN_6);
			  Tech_ans_wait = 0;

			  int32_t page_start =  i + 16 * sector_of_firmware; // number of start page
			  W25qxx_WritePage(firmware_buf + strlen(str_SIM800) + 1, page_start, 0, 256);
			  osDelay(10); //importent!!!
		  }
		  HAL_GPIO_TogglePin(GPIOA, GPIO_PIN_6);
		  osDelay(2000);
		  HAL_GPIO_TogglePin(GPIOA, GPIO_PIN_6);

		  HAL_Delay(200);
		  //";start"
		  strcpy(&(msg.str), ";start");
		  //HAL_UART_Transmit_DMA(&huart2, msg.str, MESSAGE_TYPE_BUFF_SIZE);
		  HAL_Delay(1000);
		  HAL_NVIC_SystemReset();
		  //osThreadTerminate(myTaskGetFirmHandle);
	  }

  }
  /* USER CODE END StartGetFirmware */
}

/* CallbackPingTimer function */
void CallbackPingTimer(void *argument)
{
  /* USER CODE BEGIN CallbackPingTimer */
	osSemaphoreRelease(PINGSemHandle);
  /* USER CODE END CallbackPingTimer */
}

/* CallbackDataTimer function */
void CallbackDataTimer(void *argument)
{
  /* USER CODE BEGIN CallbackDataTimer */
	Get_data = 1;
  /* USER CODE END CallbackDataTimer */
}

 /**
  * @brief  Period elapsed callback in non blocking mode
  * @note   This function is called  when TIM1 interrupt took place, inside
  * HAL_TIM_IRQHandler(). It makes a direct call to HAL_IncTick() to increment
  * a global variable "uwTick" used as application time base.
  * @param  htim : TIM handle
  * @retval None
  */
void HAL_TIM_PeriodElapsedCallback(TIM_HandleTypeDef *htim)
{
  if (htim->Instance == TIM1) {
    HAL_IncTick();
  }
}

void Error_Handler(void)
{
  __disable_irq();
  while (1)
  {
  }
}

/************************ (C) COPYRIGHT STMicroelectronics *****END OF FILE****/
